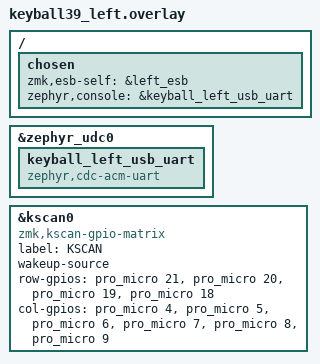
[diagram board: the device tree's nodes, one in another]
/*
 * Copyright (c) 2020 ZMK Contributors
 *
 * SPDX-License-Identifier: MIT
 */

#include "keyball39.dtsi"
#include "keyball39_esb.dtsi"

/ {
    chosen {
        zmk,esb-self = &left_esb;
        zephyr,console = &keyball_left_usb_uart;
    };
};

&zephyr_udc0 {
    keyball_left_usb_uart: keyball_left_usb_uart {
        compatible = "zephyr,cdc-acm-uart";
    };
};

&kscan0 {
    compatible = "zmk,kscan-gpio-matrix";
    label = "KSCAN";
    wakeup-source;

    row-gpios
        = <&pro_micro 21 (GPIO_ACTIVE_HIGH | GPIO_PULL_DOWN)>
        , <&pro_micro 20 (GPIO_ACTIVE_HIGH | GPIO_PULL_DOWN)>
        , <&pro_micro 19 (GPIO_ACTIVE_HIGH | GPIO_PULL_DOWN)>
        , <&pro_micro 18 (GPIO_ACTIVE_HIGH | GPIO_PULL_DOWN)>
        ;

	col-gpios
		= <&pro_micro 4 GPIO_ACTIVE_HIGH>
		, <&pro_micro 5 GPIO_ACTIVE_HIGH>
		, <&pro_micro 6 GPIO_ACTIVE_HIGH>
		, <&pro_micro 7 GPIO_ACTIVE_HIGH>
		, <&pro_micro 8 GPIO_ACTIVE_HIGH>
		, <&pro_micro 9 GPIO_ACTIVE_HIGH>
		;
};
